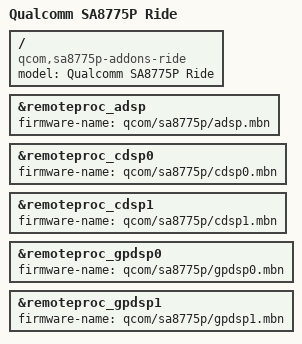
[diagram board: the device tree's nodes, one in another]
// SPDX-License-Identifier: BSD-3-Clause
/*
 * Copyright (c) 2024 Qualcomm Innovation Center, Inc. All rights reserved.
 */

/dts-v1/;

#include "sa8775p-ride.dts"
#include "sa8775p-addons-ride.dtsi"

/ {
	model = "Qualcomm SA8775P Ride";
	compatible = "qcom,sa8775p-addons-ride", "qcom,sa8775p";
};


&remoteproc_adsp {
	firmware-name = "qcom/sa8775p/adsp.mbn";
	status = "okay";
};

&remoteproc_cdsp0 {
	firmware-name = "qcom/sa8775p/cdsp0.mbn";
	status = "okay";
};

&remoteproc_cdsp1 {
	firmware-name = "qcom/sa8775p/cdsp1.mbn";
	status = "okay";
};

&remoteproc_gpdsp0 {
	firmware-name = "qcom/sa8775p/gpdsp0.mbn";
	status = "okay";
};

&remoteproc_gpdsp1 {
	firmware-name = "qcom/sa8775p/gpdsp1.mbn";
	status = "okay";
};

